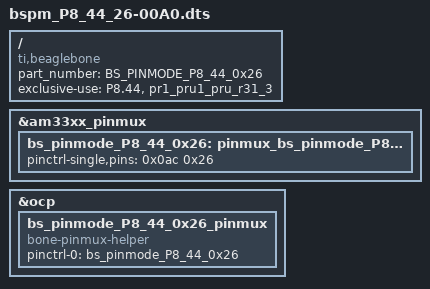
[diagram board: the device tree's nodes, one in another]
/*
 * This is a template-generated file from BoneScript
 */

/dts-v1/;
/plugin/;

/{
    compatible = "ti,beaglebone", "ti,beaglebone-black";
    part_number = "BS_PINMODE_P8_44_0x26";

    exclusive-use =
        "P8.44",
        "pr1_pru1_pru_r31_3";

    fragment@0 {
        target = <&am33xx_pinmux>;
        __overlay__ {
            bs_pinmode_P8_44_0x26: pinmux_bs_pinmode_P8_44_0x26 {
                pinctrl-single,pins = <0x0ac 0x26>;
            };
        };
    };

    fragment@1 {
        target = <&ocp>;
        __overlay__ {
            bs_pinmode_P8_44_0x26_pinmux {
                compatible = "bone-pinmux-helper";
                status = "okay";
                pinctrl-names = "default";
                pinctrl-0 = <&bs_pinmode_P8_44_0x26>;
            };
        };
    };
};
